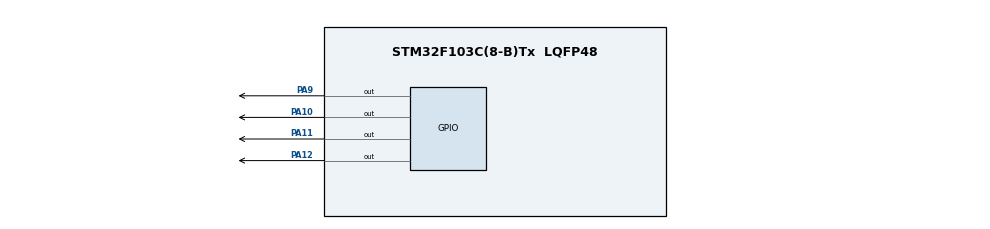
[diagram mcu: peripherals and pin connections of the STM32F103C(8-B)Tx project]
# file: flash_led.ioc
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FREERTOS.Tasks01=defaultTask,24,128,StartDefaultTask,Default,NULL,Dynamic,NULL,NULL;RedLedTask,8,128,StartRedLedTask,Default,NULL,Dynamic,NULL,NULL;GreenLedTask,8,128,StartGreenLedTask,Default,NULL,Dynamic,NULL,NULL
Mcu.Family=STM32F1
Mcu.Name=STM32F103C(8-B)Tx
Mcu.Package=LQFP48
NVIC.PriorityGroup=NVIC_PRIORITYGROUP_4
PA10.Signal=GPIO_Output
PA11.Signal=GPIO_Output
PA12.Signal=GPIO_Output
PA13.Mode=Serial_Wire
PA13.Signal=SYS_JTMS-SWDIO
PA14.Mode=Serial_Wire
PA14.Signal=SYS_JTCK-SWCLK
PA9.Signal=GPIO_Output
ProjectManager.HeapSize=0x200
ProjectManager.StackSize=0x400
ProjectManager.TargetToolchain=STM32CubeIDE
RCC.APB1Freq_Value=8000000
RCC.APB2Freq_Value=8000000
VP_FREERTOS_VS_CMSIS_V2.Mode=CMSIS_V2
board=custom

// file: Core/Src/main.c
/* USER CODE BEGIN Header */
/**
  ******************************************************************************
  * @file           : main.c
  * @brief          : Main program body
  ******************************************************************************
  * @attention
  *
  * Copyright (c) 2024 STMicroelectronics.
  * All rights reserved.
  *
  * This software is licensed under terms that can be found in the LICENSE file
  * in the root directory of this software component.
  * If no LICENSE file comes with this software, it is provided AS-IS.
  *
  ******************************************************************************
  */
/* USER CODE END Header */
#include "main.h"
#include "cmsis_os.h"

/* Definitions for defaultTask */
osThreadId_t defaultTaskHandle;
const osThreadAttr_t defaultTask_attributes = {
  .name = "defaultTask",
  .stack_size = 128 * 4,
  .priority = (osPriority_t) osPriorityNormal,
};
/* Definitions for RedLedTask */
osThreadId_t RedLedTaskHandle;
const osThreadAttr_t RedLedTask_attributes = {
  .name = "RedLedTask",
  .stack_size = 128 * 4,
  .priority = (osPriority_t) osPriorityLow,
};
/* Definitions for GreenLedTask */
osThreadId_t GreenLedTaskHandle;
const osThreadAttr_t GreenLedTask_attributes = {
  .name = "GreenLedTask",
  .stack_size = 128 * 4,
  .priority = (osPriority_t) osPriorityLow,
};

void SystemClock_Config(void);
static void MX_GPIO_Init(void);
void StartDefaultTask(void *argument);
void StartRedLedTask(void *argument);
void StartGreenLedTask(void *argument);

int main(void)
{

  /* MCU Configuration--------------------------------------------------------*/

  /* Reset of all peripherals, Initializes the Flash interface and the Systick. */
  HAL_Init();

  /* Configure the system clock */
  SystemClock_Config();

  /* Initialize all configured peripherals */
  MX_GPIO_Init();

  /* Init scheduler */
  osKernelInitialize();

  /* Create the thread(s) */
  /* creation of defaultTask */
  defaultTaskHandle = osThreadNew(StartDefaultTask, NULL, &defaultTask_attributes);

  /* creation of RedLedTask */
  RedLedTaskHandle = osThreadNew(StartRedLedTask, NULL, &RedLedTask_attributes);

  /* creation of GreenLedTask */
  GreenLedTaskHandle = osThreadNew(StartGreenLedTask, NULL, &GreenLedTask_attributes);

  /* Start scheduler */
  osKernelStart();

  /* We should never get here as control is now taken by the scheduler */

  /* Infinite loop */
  while (1)
  {

  }
}

void SystemClock_Config(void)
{
  RCC_OscInitTypeDef RCC_OscInitStruct = {0};
  RCC_ClkInitTypeDef RCC_ClkInitStruct = {0};

  /** Initializes the RCC Oscillators according to the specified parameters
  * in the RCC_OscInitTypeDef structure.
  */
  RCC_OscInitStruct.OscillatorType = RCC_OSCILLATORTYPE_HSI;
  RCC_OscInitStruct.HSIState = RCC_HSI_ON;
  RCC_OscInitStruct.HSICalibrationValue = RCC_HSICALIBRATION_DEFAULT;
  RCC_OscInitStruct.PLL.PLLState = RCC_PLL_NONE;
  if (HAL_RCC_OscConfig(&RCC_OscInitStruct) != HAL_OK)
  {
    Error_Handler();
  }

  /** Initializes the CPU, AHB and APB buses clocks
  */
  RCC_ClkInitStruct.ClockType = RCC_CLOCKTYPE_HCLK|RCC_CLOCKTYPE_SYSCLK
                              |RCC_CLOCKTYPE_PCLK1|RCC_CLOCKTYPE_PCLK2;
  RCC_ClkInitStruct.SYSCLKSource = RCC_SYSCLKSOURCE_HSI;
  RCC_ClkInitStruct.AHBCLKDivider = RCC_SYSCLK_DIV1;
  RCC_ClkInitStruct.APB1CLKDivider = RCC_HCLK_DIV1;
  RCC_ClkInitStruct.APB2CLKDivider = RCC_HCLK_DIV1;

  if (HAL_RCC_ClockConfig(&RCC_ClkInitStruct, FLASH_LATENCY_0) != HAL_OK)
  {
    Error_Handler();
  }
}

static void MX_GPIO_Init(void)
{
  GPIO_InitTypeDef GPIO_InitStruct = {0};

  /* GPIO Ports Clock Enable */
  __HAL_RCC_GPIOA_CLK_ENABLE();

  /*Configure GPIO pin Output Level */
  HAL_GPIO_WritePin(GPIOA, GPIO_PIN_9|GPIO_PIN_10|GPIO_PIN_11|GPIO_PIN_12, GPIO_PIN_RESET);

  /*Configure GPIO pins : PA9 PA10 PA11 PA12 */
  GPIO_InitStruct.Pin = GPIO_PIN_9|GPIO_PIN_10|GPIO_PIN_11|GPIO_PIN_12;
  GPIO_InitStruct.Mode = GPIO_MODE_OUTPUT_PP;
  GPIO_InitStruct.Pull = GPIO_NOPULL;
  GPIO_InitStruct.Speed = GPIO_SPEED_FREQ_LOW;
  HAL_GPIO_Init(GPIOA, &GPIO_InitStruct);

}

void StartDefaultTask(void *argument)
{
  for(;;)
  {
    osDelay(1);
  }
}

void StartRedLedTask(void *argument)
{
  /* USER CODE BEGIN StartRedLedTask */
  /* Infinite loop */
  for(;;)
  {
	HAL_GPIO_TogglePin(GPIOA, GPIO_PIN_10);
	HAL_GPIO_TogglePin(GPIOA, GPIO_PIN_9);
    osDelay(1000);
  }
  /* USER CODE END StartRedLedTask */
}

void StartGreenLedTask(void *argument)
{
  /* USER CODE BEGIN StartGreenLedTask */
  /* Infinite loop */
  for(;;)
  {
	HAL_GPIO_TogglePin(GPIOA, GPIO_PIN_12);
	HAL_GPIO_TogglePin(GPIOA, GPIO_PIN_11);
    osDelay(500);
  }
  /* USER CODE END StartGreenLedTask */
}

void Error_Handler(void)
{
  __disable_irq();
  while (1)
  {
  }
}
